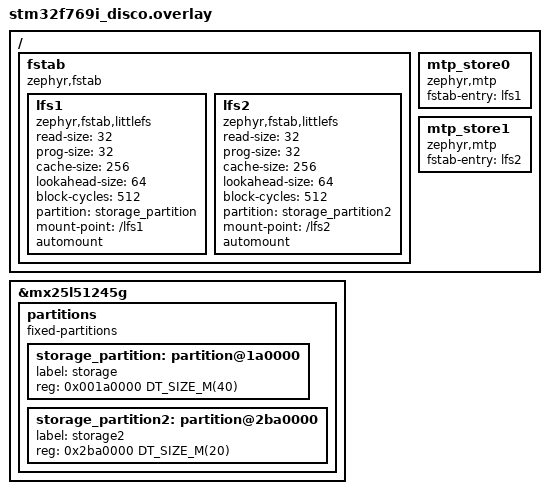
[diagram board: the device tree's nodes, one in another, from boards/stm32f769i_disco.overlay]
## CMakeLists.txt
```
# SPDX-License-Identifier: Apache-2.0

cmake_minimum_required(VERSION 3.20.0)
find_package(Zephyr REQUIRED HINTS $ENV{ZEPHYR_BASE})
project(mtp)

include(${ZEPHYR_BASE}/samples/subsys/usb/common/common.cmake)
file(GLOB app_sources src/*.c)
target_sources(app PRIVATE ${app_sources})
```

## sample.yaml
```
sample:
  name: MTP USB
tests:
  sample.usb.mtp:
    depends_on: usb_device
    tags: usb
    arch_exclude: posix
    harness: console
    harness_config:
      type: one_line
      regex:
        - "Wait for DTR"
  sample.usb_device_next.mtp:
    depends_on: usbd
    tags: usb
    extra_args: CONF_FILE="usbd_next_prj.conf"
    integration_platforms:
      - nrf52840dk/nrf52840
      - nrf54h20dk/nrf54h20/cpuapp
      - frdm_k64f
      - stm32f723e_disco
      - nucleo_f413zh
      - mimxrt685_evk/mimxrt685s/cm33
      - mimxrt1060_evk
    harness: console
    harness_config:
      type: one_line
      regex:
        - "Wait for DTR"
  sample.usb.mtp.buildonly:
    depends_on: usb_device
    tags: usb
    arch_allow: posix
    build_only: true
    integration_platforms:
      - native_sim
```

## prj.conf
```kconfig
CONFIG_USB_DEVICE_STACK_NEXT=y
CONFIG_USB_DEVICE_INITIALIZE_AT_BOOT=n
CONFIG_USBD_MTP_CLASS=y

CONFIG_SAMPLE_USBD_PRODUCT="USBD MTP sample"
CONFIG_SAMPLE_USBD_PID=0x0012

CONFIG_LOG=y
CONFIG_USBD_LOG_LEVEL_WRN=y
CONFIG_USBD_MTP_LOG_LEVEL_ERR=y

CONFIG_DISK_ACCESS=y
CONFIG_DISK_DRIVERS=y
CONFIG_FILE_SYSTEM=y
CONFIG_FILE_SYSTEM_MKFS=y
CONFIG_FAT_FILESYSTEM_ELM=y
CONFIG_FS_FATFS_FSTAB_AUTOMOUNT=y
CONFIG_FS_FATFS_LFN=y

CONFIG_USBD_THREAD_STACK_SIZE=4096
CONFIG_MAIN_STACK_SIZE=2048
```

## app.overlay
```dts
/*
 * Copyright (c) 2025 Mohamed ElShahawi (extremegtx@hotmail.com)
 *
 * SPDX-License-Identifier: Apache-2.0
 */

/ {
	ramdisk0 {
		compatible = "zephyr,ram-disk";
		disk-name = "RAM";
		sector-size = <512>;
		sector-count = <128>;
	};

	fstab {
		compatible = "zephyr,fstab";

		ffs1: ffs1 {
			compatible = "zephyr,fstab,fatfs";
			automount;
			disk-access;
			mount-point = "/RAM:";
		};
	};
};
```

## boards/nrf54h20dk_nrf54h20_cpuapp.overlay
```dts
/*
 * Copyright (c) 2024 Kelly Lord
 *
 * SPDX-License-Identifier: Apache-2.0
 */

/ {
	fstab {
		compatible = "zephyr,fstab";

		lfs1: lfs1 {
			compatible = "zephyr,fstab,littlefs";
			read-size = <32>;
			prog-size = <32>;
			cache-size = <256>;
			lookahead-size = <64>;
			block-cycles = <512>;
			partition = <&storage_partition>;
			mount-point = "/lfs1";
			automount;
		};
	};

	mtp_store0 {
		status = "okay";
		compatible = "zephyr,mtp";
		fstab-entry = <&lfs1>;
	};
};
```

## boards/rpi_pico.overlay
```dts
/*
 * Copyright (c) 2024 Kelly Lord
 *
 * SPDX-License-Identifier: Apache-2.0
 */

&flash0 {
	partitions {
		compatible = "fixed-partitions";
		#address-cells = <1>;
		#size-cells = <1>;

		storage_partition: partition@100000 {
			label = "storage";
			reg = <0x100000 DT_SIZE_M(1)>;
		};
	};
};

/ {
	fstab {
		compatible = "zephyr,fstab";

		lfs1: lfs1 {
			compatible = "zephyr,fstab,littlefs";
			read-size = <32>;
			prog-size = <32>;
			cache-size = <256>;
			lookahead-size = <64>;
			block-cycles = <512>;
			partition = <&storage_partition>;
			mount-point = "/lfs1";
			automount;
		};
	};

	mtp_store0 {
		status = "okay";
		compatible = "zephyr,mtp";
		fstab-entry = <&lfs1>;
	};
};
```

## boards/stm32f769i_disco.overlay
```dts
/*
 * Copyright (c) 2025 Mohamed ElShahawi (extremegtx@hotmail.com)
 *
 * SPDX-License-Identifier: Apache-2.0
 */

/delete-node/ &storage_partition;

&mx25l51245g {
	partitions {
		compatible = "fixed-partitions";
		#address-cells = <1>;
		#size-cells = <1>;

		storage_partition: partition@1a0000 {
			label = "storage";
			reg = <0x001a0000 DT_SIZE_M(40)>;
		};

		storage_partition2: partition@2ba0000 {
			label = "storage2";
			reg = <0x2ba0000 DT_SIZE_M(20)>;
		};
	};
};

/ {
	fstab {
		compatible = "zephyr,fstab";

		lfs1: lfs1 {
			compatible = "zephyr,fstab,littlefs";
			read-size = <32>;
			prog-size = <32>;
			cache-size = <256>;
			lookahead-size = <64>;
			block-cycles = <512>;
			partition = <&storage_partition>;
			mount-point = "/lfs1";
			automount;
		};

		lfs2: lfs2 {
			compatible = "zephyr,fstab,littlefs";
			read-size = <32>;
			prog-size = <32>;
			cache-size = <256>;
			lookahead-size = <64>;
			block-cycles = <512>;
			partition = <&storage_partition2>;
			mount-point = "/lfs2";
			automount;
		};
	};

	mtp_store0 {
		status = "okay";
		compatible = "zephyr,mtp";
		fstab-entry = <&lfs1>;
	};

	mtp_store1 {
		status = "okay";
		compatible = "zephyr,mtp";
		fstab-entry = <&lfs2>;
	};
};
```

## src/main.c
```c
/*
 * Copyright (c) 2019 Intel Corporation
 * Copyright (c) 2025 Mohamed ElShahawi (extremegtx@hotmail.com)
 *
 * SPDX-License-Identifier: Apache-2.0
 */

/**
 * @file
 * @brief Sample app for USB MTP class
 *
 * Sample app for USB MTP class driver.
 */

#include <sample_usbd.h>

#include <zephyr/devicetree.h>
#include <zephyr/kernel.h>
#include <zephyr/usb/class/usbd_mtp.h>
#include <zephyr/usb/usbd.h>
#include <zephyr/logging/log.h>
LOG_MODULE_REGISTER(usb_mtp_sample, LOG_LEVEL_INF);

USBD_MTP_DEFINE_INSTANCE(ram, "ZEPHYR", "Zephyr MTP", "1.0",
			 "0123456789ABCDEF0123456789ABCDEF",
			 USBD_MTP_STORAGE_ENTRY(DT_PROP(DT_NODELABEL(ffs1), mount_point),
						DT_PROP(DT_NODELABEL(ffs1), read_only)));

static void sample_msg_cb(struct usbd_context *const ctx, const struct usbd_msg *msg)
{
	LOG_INF("USBD message: %s", usbd_msg_type_string(msg->type));

	if (usbd_can_detect_vbus(ctx)) {
		if (msg->type == USBD_MSG_VBUS_READY) {
			if (usbd_enable(ctx)) {
				LOG_ERR("Failed to enable device support");
			}
		}

		if (msg->type == USBD_MSG_VBUS_REMOVED) {
			if (usbd_disable(ctx)) {
				LOG_ERR("Failed to disable device support");
			}
		}
	}
}

int main(void)
{
	struct usbd_context *sample_usbd;
	int ret;

	sample_usbd = sample_usbd_init_device(sample_msg_cb);
	if (sample_usbd == NULL) {
		LOG_ERR("Failed to initialize USB device");
		return -ENODEV;
	}

	if (!usbd_can_detect_vbus(sample_usbd)) {
		/* doc device enable start */
		ret = usbd_enable(sample_usbd);
		if (ret) {
			LOG_ERR("Failed to enable device support");
			return ret;
		}
		/* doc device enable end */
	}

	LOG_INF("USB device support enabled\n");
	return 0;
}
```
